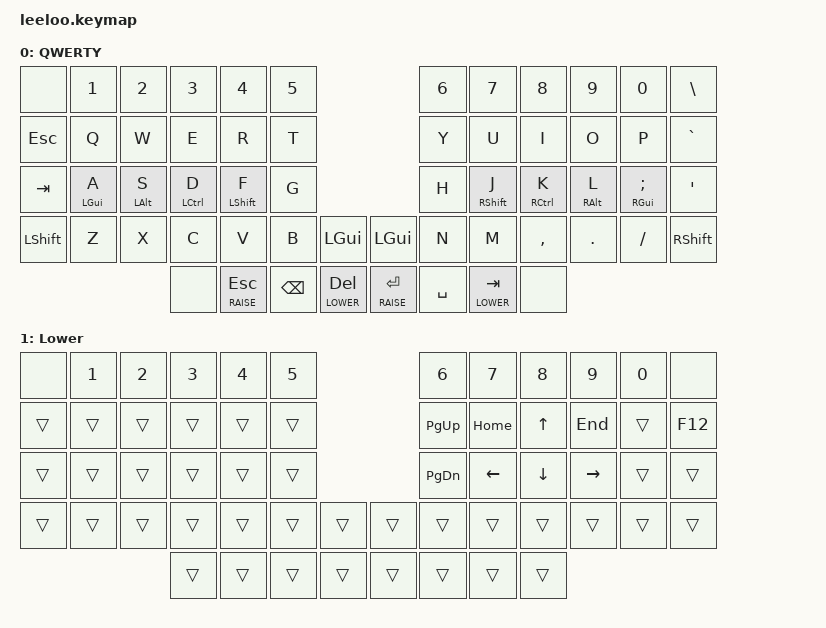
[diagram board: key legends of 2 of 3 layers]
/*
 * Copyright (c) 2023 The ZMK Contributors
 * SPDX-License-Identifier: MIT
 */

#include <behaviors.dtsi>
#include <dt-bindings/zmk/outputs.h>
#include <dt-bindings/zmk/keys.h>
#include <dt-bindings/zmk/bt.h>

// Layers
#define DEFAULT    0       // default_layer
#define LOWER      1       // lower_layer
#define RAISE      2       // raise_layer

&mt {
    flavor = "tap-preferred";
    tapping_term_ms = <400>;
};

/*
 * Assign the cs-gpios pin to 4.
 * Uncomment these next few lines if implementing nice!view Displays
 * A wire from the nice!view CS display needs to be connected to the
 * High Frequency P0.22, also known as D4 if you choose to refer to
 * the pins with Arduino Labels.
 */
//nice_view_spi: &spi0 {
//  cs-gpios = <&pro_micro 4 GPIO_ACTIVE_HIGH>;
//};

/ {

    keymap {
        compatible = "zmk,keymap";

        default_layer {
            display-name = " QWERTY";
            bindings = <
&none    &kp N1     &kp N2     &kp N3     &kp N4     &kp N5                           &kp N6     &kp N7     &kp N8     &kp N9     &kp N0     &kp BSLH
&kp ESC  &kp Q      &kp W      &kp E      &kp R      &kp T                            &kp Y      &kp U      &kp I      &kp O      &kp P      &kp GRAVE
&kp TAB   &mt  LGUI A       &mt  LALT S      &mt  LCTRL D      &mt LSHIFT F      &kp G     &kp H      &mt RSHIFT J &mt RCTRL K &mt RALT L &mt RGUI SEMI &kp SQT
&kp LSHFT &kp Z      &kp X      &kp C      &kp V      &kp B     &kp LGUI    &kp LGUI   &kp N      &kp M      &kp COMMA  &kp DOT    &kp FSLH   &kp RSHFT
                             &none   &lt RAISE ESC  &kp BSPC  &lt LOWER DEL    &lt RAISE ENTER  &kp SPACE  &lt LOWER TAB   &none
            >;

            sensor-bindings = <&inc_dec_kp C_VOL_UP C_VOL_DN>;
        };

        lower_layer {
            display-name = " Lower";
            bindings = <
&none      &kp N1     &kp N2     &kp N3     &kp N4     &kp N5                           &kp N6     &kp N7     &kp N8     &kp N9     &kp N0     &none
&trans     &trans     &trans     &trans     &trans     &trans                           &kp PG_UP  &kp HOME   &kp UP     &kp END    &trans     &kp F12
&trans     &trans     &trans     &trans     &trans     &trans                           &kp PG_DN  &kp LEFT   &kp DOWN   &kp RIGHT  &trans     &trans
&trans     &trans     &trans     &trans     &trans     &trans     &trans     &trans     &trans     &trans     &trans     &trans     &trans     &trans
                                 &trans     &trans     &trans     &trans     &trans     &trans     &trans     &trans
            >;

            sensor-bindings = <&inc_dec_kp C_VOL_UP C_VOL_DN>;
        };

        raise_layer {
            display-name = " Raise";
            bindings = <
&trans     &trans     &trans     &trans     &trans     &trans                           &trans        &trans        &trans        &trans       &trans        &trans
&trans     &kp GRAVE   &kp LBRC   &kp RBRC   &kp PIPE   &kp BSLH                           &trans        &kp N7        &kp N8        &kp N9       &trans        &trans
&trans     &kp TILDE   &kp LPAR   &kp RPAR   &kp MINUS  &kp EQUAL                           &trans        &kp N4        &kp N5        &kp N6       &trans        &trans
&trans     &trans    &kp LBKT   &kp RBKT   &kp UNDER  &kp PLUS    &trans     &trans     &kp N0        &kp N1        &kp N2        &kp N3        &trans        &trans        &trans
                                 &trans     &trans     &trans     &trans     &trans     &trans        &trans    &trans
            >;

            sensor-bindings = <&inc_dec_kp C_VOL_UP C_VOL_DN>;
        };

    };
};
